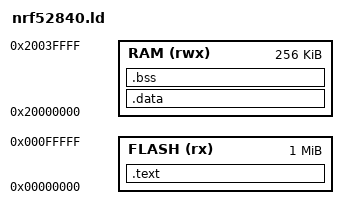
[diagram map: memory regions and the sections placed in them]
MEMORY {
    FLASH (rx)  : ORIGIN = 0x00000000, LENGTH = 1024K
    RAM   (rwx) : ORIGIN = 0x20000000, LENGTH = 256K
}

ENTRY(Reset_Handler)

SECTIONS {
    .text : {
        KEEP(*(.isr_vector))
        *(.text*)
        *(.rodata*)
    } > FLASH

    .data : {
        *(.data*)
    } > RAM
    ASSERT(SIZEOF(.data) == 0, "startup does not copy .data; keep statics zero-init")

    .bss (NOLOAD) : {
        _sbss = .;
        *(.bss*)
        *(COMMON)
        _ebss = .;
    } > RAM
}

_estack = ORIGIN(RAM) + LENGTH(RAM);
